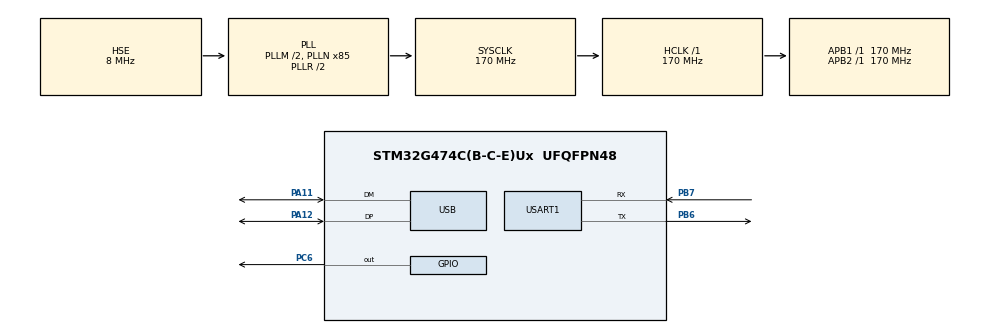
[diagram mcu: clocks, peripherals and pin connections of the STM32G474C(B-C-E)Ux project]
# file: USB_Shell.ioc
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Mcu.Family=STM32G4
Mcu.Name=STM32G474C(B-C-E)Ux
Mcu.Package=UFQFPN48
NVIC.PriorityGroup=NVIC_PRIORITYGROUP_4
NVIC.TIM1_BRK_TIM15_IRQn=true\:15\:0\:false\:false\:true\:false\:true\:true
NVIC.TIM5_IRQn=true\:15\:0\:false\:false\:true\:true\:true\:true
NVIC.TimeBase=TIM1_BRK_TIM15_IRQn
NVIC.TimeBaseIP=TIM15
NVIC.USART1_IRQn=true\:0\:0\:false\:false\:true\:true\:true\:true
NVIC.USB_LP_IRQn=true\:0\:0\:false\:false\:true\:false\:true\:true
PA11.Mode=Device
PA11.Signal=USB_DM
PA12.Mode=Device
PA12.Signal=USB_DP
PA13.Mode=Serial_Wire
PA13.Signal=SYS_JTMS-SWDIO
PA14.Mode=Serial_Wire
PA14.Signal=SYS_JTCK-SWCLK
PB6.Mode=Asynchronous
PB6.Signal=USART1_TX
PB7.Mode=Asynchronous
PB7.Signal=USART1_RX
PC6.PinState=GPIO_PIN_SET
PC6.Signal=GPIO_Output
PF0-OSC_IN.Mode=HSE-External-Oscillator
PF0-OSC_IN.Signal=RCC_OSC_IN
PF1-OSC_OUT.Mode=HSE-External-Oscillator
PF1-OSC_OUT.Signal=RCC_OSC_OUT
ProjectManager.HeapSize=0x800
ProjectManager.StackSize=0x800
ProjectManager.TargetToolchain=STM32CubeIDE
RCC.ADC12Freq_Value=170000000
RCC.ADC345Freq_Value=170000000
RCC.AHBFreq_Value=170000000
RCC.APB1Freq_Value=170000000
RCC.APB1TimFreq_Value=170000000
RCC.APB2Freq_Value=170000000
RCC.APB2TimFreq_Value=170000000
RCC.CK48CLockSelection=RCC_USBCLKSOURCE_HSI48
RCC.CortexFreq_Value=170000000
RCC.EXTERNAL_CLOCK_VALUE=12288000
RCC.HCLKFreq_Value=170000000
RCC.HSE_VALUE=8000000
RCC.HSI48_VALUE=48000000
RCC.HSI_VALUE=16000000
RCC.LSE_VALUE=32768
RCC.PLLM=RCC_PLLM_DIV2
RCC.PLLN=85
RCC.PLLSourceVirtual=RCC_PLLSOURCE_HSE
RCC.SYSCLKFreq_VALUE=170000000
RCC.SYSCLKSource=RCC_SYSCLKSOURCE_PLLCLK
RCC.USBFreq_Value=48000000
RCC.VCOOutputFreq_Value=340000000
TIM5.PeriodNoDither=500000-1
TIM5.Prescaler=170-1
USART1.VirtualMode-Asynchronous=VM_ASYNC
USB_DEVICE.CLASS_NAME_FS=CDC
USB_DEVICE.USBD_MAX_NUM_CONFIGURATION=1
USB_DEVICE.USBD_MAX_NUM_INTERFACES=1
USB_DEVICE.VirtualMode=Cdc
USB_DEVICE.VirtualModeFS=Cdc_FS
VP_SYS_VS_DBSignals.Mode=DisableDeadBatterySignals
VP_SYS_VS_tim15.Mode=TIM15
VP_TIM5_VS_ClockSourceINT.Mode=Internal
VP_USB_DEVICE_VS_USB_DEVICE_CDC_FS.Mode=CDC_FS
board=custom

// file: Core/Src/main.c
/* USER CODE BEGIN Header */
/**
  ******************************************************************************
  * @file           : main.c
  * @brief          : Main program body
  ******************************************************************************
  * @attention
  *
  * Copyright (c) 2025 STMicroelectronics.
  * All rights reserved.
  *
  * This software is licensed under terms that can be found in the LICENSE file
  * in the root directory of this software component.
  * If no LICENSE file comes with this software, it is provided AS-IS.
  *
  ******************************************************************************
  */
/* USER CODE END Header */
#include "main.h"
#include "usb_device.h"

/* USER CODE BEGIN Includes */
#include "usbd_cdc_if.h"
/* USER CODE END Includes */

TIM_HandleTypeDef htim5;

UART_HandleTypeDef huart1;

/* USER CODE BEGIN PV */
char str_tx[21];
/* USER CODE END PV */

void SystemClock_Config(void);
static void MX_GPIO_Init(void);
static void MX_USART1_UART_Init(void);
static void MX_TIM5_Init(void);
/* USER CODE BEGIN PFP */
void init(void);
void loop(void);
/* USER CODE END PFP */

/* USER CODE BEGIN 0 */
//
void init()
{
	HAL_TIM_Base_Start_IT(&htim5);
	sprintf(str_tx, "USB Transmit\r\n");

	return;
}

//
void loop()
{
	return;
}
/* USER CODE END 0 */

int main(void)
{

  /* MCU Configuration--------------------------------------------------------*/

  /* Reset of all peripherals, Initializes the Flash interface and the Systick. */
  HAL_Init();

  /* Configure the system clock */
  SystemClock_Config();

  /* Initialize all configured peripherals */
  MX_GPIO_Init();
  MX_USART1_UART_Init();
  MX_USB_Device_Init();
  MX_TIM5_Init();
  /* USER CODE BEGIN 2 */
  init();
  /* USER CODE END 2 */

  /* Infinite loop */
  /* USER CODE BEGIN WHILE */
  while (1)
  {
	loop();
    /* USER CODE END WHILE */

  }
}

void SystemClock_Config(void)
{
  RCC_OscInitTypeDef RCC_OscInitStruct = {0};
  RCC_ClkInitTypeDef RCC_ClkInitStruct = {0};

  /** Configure the main internal regulator output voltage
  */
  HAL_PWREx_ControlVoltageScaling(PWR_REGULATOR_VOLTAGE_SCALE1_BOOST);

  /** Initializes the RCC Oscillators according to the specified parameters
  * in the RCC_OscInitTypeDef structure.
  */
  RCC_OscInitStruct.OscillatorType = RCC_OSCILLATORTYPE_HSI48|RCC_OSCILLATORTYPE_HSE;
  RCC_OscInitStruct.HSEState = RCC_HSE_ON;
  RCC_OscInitStruct.HSI48State = RCC_HSI48_ON;
  RCC_OscInitStruct.PLL.PLLState = RCC_PLL_ON;
  RCC_OscInitStruct.PLL.PLLSource = RCC_PLLSOURCE_HSE;
  RCC_OscInitStruct.PLL.PLLM = RCC_PLLM_DIV2;
  RCC_OscInitStruct.PLL.PLLN = 85;
  RCC_OscInitStruct.PLL.PLLP = RCC_PLLP_DIV2;
  RCC_OscInitStruct.PLL.PLLQ = RCC_PLLQ_DIV2;
  RCC_OscInitStruct.PLL.PLLR = RCC_PLLR_DIV2;
  if (HAL_RCC_OscConfig(&RCC_OscInitStruct) != HAL_OK)
  {
    Error_Handler();
  }

  /** Initializes the CPU, AHB and APB buses clocks
  */
  RCC_ClkInitStruct.ClockType = RCC_CLOCKTYPE_HCLK|RCC_CLOCKTYPE_SYSCLK
                              |RCC_CLOCKTYPE_PCLK1|RCC_CLOCKTYPE_PCLK2;
  RCC_ClkInitStruct.SYSCLKSource = RCC_SYSCLKSOURCE_PLLCLK;
  RCC_ClkInitStruct.AHBCLKDivider = RCC_SYSCLK_DIV1;
  RCC_ClkInitStruct.APB1CLKDivider = RCC_HCLK_DIV1;
  RCC_ClkInitStruct.APB2CLKDivider = RCC_HCLK_DIV1;

  if (HAL_RCC_ClockConfig(&RCC_ClkInitStruct, FLASH_LATENCY_4) != HAL_OK)
  {
    Error_Handler();
  }
}

static void MX_TIM5_Init(void)
{

  TIM_ClockConfigTypeDef sClockSourceConfig = {0};
  TIM_MasterConfigTypeDef sMasterConfig = {0};

  htim5.Instance = TIM5;
  htim5.Init.Prescaler = 170-1;
  htim5.Init.CounterMode = TIM_COUNTERMODE_UP;
  htim5.Init.Period = 499999;
  htim5.Init.ClockDivision = TIM_CLOCKDIVISION_DIV1;
  htim5.Init.AutoReloadPreload = TIM_AUTORELOAD_PRELOAD_DISABLE;
  if (HAL_TIM_Base_Init(&htim5) != HAL_OK)
  {
    Error_Handler();
  }
  sClockSourceConfig.ClockSource = TIM_CLOCKSOURCE_INTERNAL;
  if (HAL_TIM_ConfigClockSource(&htim5, &sClockSourceConfig) != HAL_OK)
  {
    Error_Handler();
  }
  sMasterConfig.MasterOutputTrigger = TIM_TRGO_RESET;
  sMasterConfig.MasterSlaveMode = TIM_MASTERSLAVEMODE_DISABLE;
  if (HAL_TIMEx_MasterConfigSynchronization(&htim5, &sMasterConfig) != HAL_OK)
  {
    Error_Handler();
  }

}

static void MX_USART1_UART_Init(void)
{

  huart1.Instance = USART1;
  huart1.Init.BaudRate = 115200;
  huart1.Init.WordLength = UART_WORDLENGTH_8B;
  huart1.Init.StopBits = UART_STOPBITS_1;
  huart1.Init.Parity = UART_PARITY_NONE;
  huart1.Init.Mode = UART_MODE_TX_RX;
  huart1.Init.HwFlowCtl = UART_HWCONTROL_NONE;
  huart1.Init.OverSampling = UART_OVERSAMPLING_16;
  huart1.Init.OneBitSampling = UART_ONE_BIT_SAMPLE_DISABLE;
  huart1.Init.ClockPrescaler = UART_PRESCALER_DIV1;
  huart1.AdvancedInit.AdvFeatureInit = UART_ADVFEATURE_NO_INIT;
  if (HAL_UART_Init(&huart1) != HAL_OK)
  {
    Error_Handler();
  }
  if (HAL_UARTEx_SetTxFifoThreshold(&huart1, UART_TXFIFO_THRESHOLD_1_8) != HAL_OK)
  {
    Error_Handler();
  }
  if (HAL_UARTEx_SetRxFifoThreshold(&huart1, UART_RXFIFO_THRESHOLD_1_8) != HAL_OK)
  {
    Error_Handler();
  }
  if (HAL_UARTEx_DisableFifoMode(&huart1) != HAL_OK)
  {
    Error_Handler();
  }

}

static void MX_GPIO_Init(void)
{
  GPIO_InitTypeDef GPIO_InitStruct = {0};

  /* GPIO Ports Clock Enable */
  __HAL_RCC_GPIOF_CLK_ENABLE();
  __HAL_RCC_GPIOC_CLK_ENABLE();
  __HAL_RCC_GPIOA_CLK_ENABLE();
  __HAL_RCC_GPIOB_CLK_ENABLE();

  /*Configure GPIO pin Output Level */
  HAL_GPIO_WritePin(GPIOC, GPIO_PIN_6, GPIO_PIN_SET);

  /*Configure GPIO pin : PC6 */
  GPIO_InitStruct.Pin = GPIO_PIN_6;
  GPIO_InitStruct.Mode = GPIO_MODE_OUTPUT_PP;
  GPIO_InitStruct.Pull = GPIO_NOPULL;
  GPIO_InitStruct.Speed = GPIO_SPEED_FREQ_LOW;
  HAL_GPIO_Init(GPIOC, &GPIO_InitStruct);

}

void HAL_TIM_PeriodElapsedCallback(TIM_HandleTypeDef *htim)
{
  if (htim->Instance == TIM15)
  {
    HAL_IncTick();
  }
  /* USER CODE BEGIN Callback 1 */
  if (htim->Instance == TIM5)
  {
    HAL_GPIO_TogglePin(GPIOC, GPIO_PIN_6);
//    CDC_Transmit_FS((unsigned char*)str_tx, strlen(str_tx));
  }

  /* USER CODE END Callback 1 */
}

void Error_Handler(void)
{
  __disable_irq();
  while (1)
  {
  }
}
